# nRF54h20_sysctrl register map
Vendor: Nordic Semiconductor; Series: nRF54h; File version: 1
Registers are 32-bit, read-write, reset 0x0 unless marked. A register's access mark holds for its fields unless they carry their own. Offsets are from the block's base; [hi:lo] are bit positions; lines under a group give offsets from that group; {n}, {i} and the like mark numbered series; 'fields as' and 'values as' point back to an identical list.

## GLOBAL_EGU130 — Event generator unit
Base 0x5F92D000
{0x0+4i} TASKS_TRIGGER[{i}] (i=0..15) wo — Description collection: Trigger n for triggering the corresponding TRIGGERED[n] event
  [0] TASKS_TRIGGER — Trigger n for triggering the corresponding TRIGGERED[n] event
    1=Trigger task
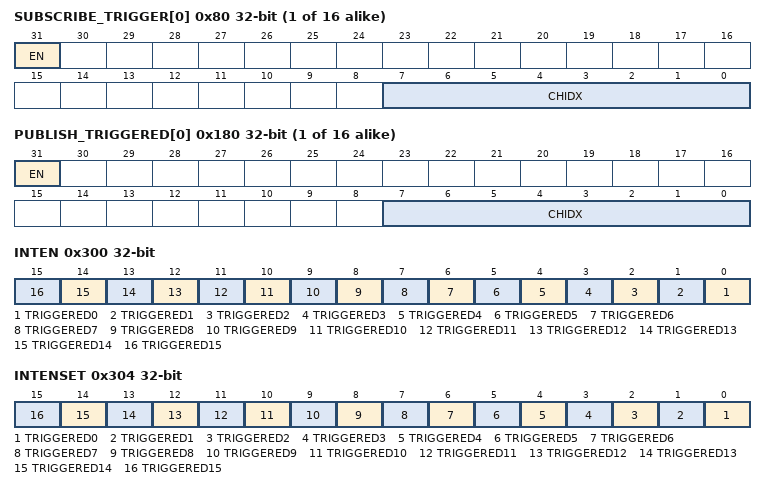
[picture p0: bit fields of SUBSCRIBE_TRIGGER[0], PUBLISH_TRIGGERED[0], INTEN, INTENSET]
{0x80+4i} SUBSCRIBE_TRIGGER[{i}] (i=0..15) — Description collection: Subscribe configuration for task TRIGGER[n]
  [31] EN
    0=Disabled (Disable subscription); 1=Enabled (Enable subscription)
  [7:0] CHIDX — DPPI channel that task TRIGGER[n] will subscribe to
{0x100+4i} EVENTS_TRIGGERED[{i}] (i=0..15) — Description collection: Event number n generated by triggering the corresponding TRIGGER[n] task
  [0] EVENTS_TRIGGERED — Event number n generated by triggering the corresponding TRIGGER[n] task
    0=NotGenerated (Event not generated); 1=Generated (Event generated)
{0x180+4i} PUBLISH_TRIGGERED[{i}] (i=0..15) — Description collection: Publish configuration for event TRIGGERED[n]
  [31] EN
    0=Disabled (Disable publishing); 1=Enabled (Enable publishing)
  [7:0] CHIDX — DPPI channel that event TRIGGERED[n] will publish to
0x300 INTEN — Enable or disable interrupt
  [all] fields
    0=Disabled; 1=Enabled
  [n] TRIGGERED{n} (n=0..15) — Enable or disable interrupt for event TRIGGERED[{n}]
0x304 INTENSET — Enable interrupt
  [all] fields
    on read: 0=Disabled (Read: Disabled); 1=Enabled (Read: Enabled) | on write: 1=Set (Enable)
  [n] TRIGGERED{n} (n=0..15) — Write '1' to enable interrupt for event TRIGGERED[{n}]
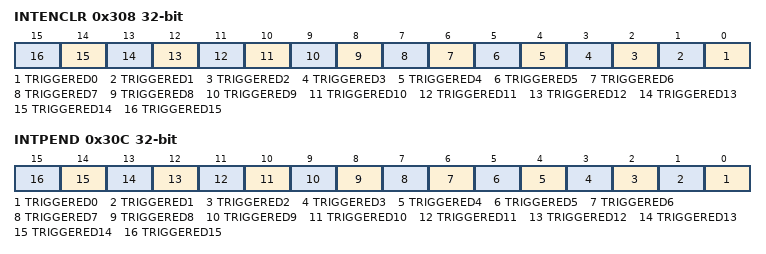
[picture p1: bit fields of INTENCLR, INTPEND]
0x308 INTENCLR — Disable interrupt
  [all] fields
    on read: 0=Disabled (Read: Disabled); 1=Enabled (Read: Enabled) | on write: 1=Clear (Disable)
  [n] TRIGGERED{n} (n=0..15) — Write '1' to disable interrupt for event TRIGGERED[{n}]
0x30C INTPEND ro — Pending interrupts
  [all] fields
    on read: 0=NotPending (Read: Not pending); 1=Pending (Read: Pending)
  [n] TRIGGERED{n} (n=0..15) — Read pending status of interrupt for event TRIGGERED[{n}]

## VDETPOF5V0 — VDETPOF5V0 peripheral
Base 0x5F979000
0x00 TASKS_PWRUP wo — Power up voltage detector
  [0] TASKS_PWRUP
    1=Trigger task
0x04 TASKS_PWRDOWN wo — Power down voltage detector
  [0] TASKS_PWRDOWN
    1=Trigger task
0x100 EVENTS_READY — Power up done
  [0] EVENTS_READY
    0=NotGenerated (Event not generated); 1=Generated (Event generated)
0x108 EVENTS_POFWARN — Power failure warning
  [0] EVENTS_POFWARN
    values as EVENTS_READY.EVENTS_READY
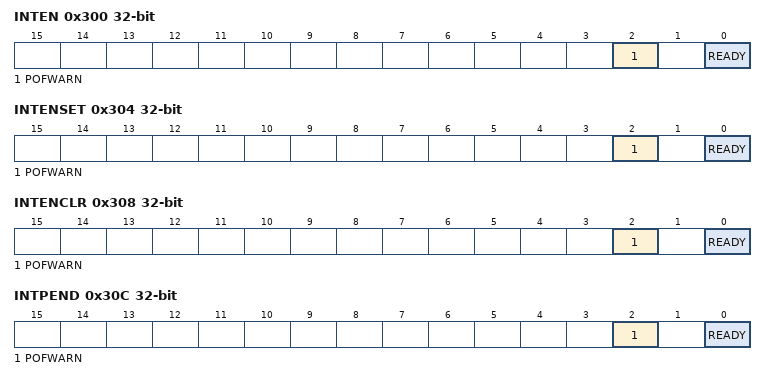
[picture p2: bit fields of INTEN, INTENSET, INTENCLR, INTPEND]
0x300 INTEN — Enable or disable interrupt
  [2] POFWARN — Enable or disable interrupt for event POFWARN
    0=Disabled; 1=Enabled
  [0] READY — Enable or disable interrupt for event READY
    0=Disabled; 1=Enabled
0x304 INTENSET — Enable interrupt
  [2] POFWARN — Write '1' to enable interrupt for event POFWARN
    on read: 0=Disabled (Read: Disabled); 1=Enabled (Read: Enabled) | on write: 1=Set (Enable)
  [0] READY — Write '1' to enable interrupt for event READY
    values as POFWARN
0x308 INTENCLR — Disable interrupt
  [2] POFWARN — Write '1' to disable interrupt for event POFWARN
    on read: 0=Disabled (Read: Disabled); 1=Enabled (Read: Enabled) | on write: 1=Clear (Disable)
  [0] READY — Write '1' to disable interrupt for event READY
    values as POFWARN
0x30C INTPEND ro — Pending interrupts
  [2] POFWARN — Read pending status of interrupt for event POFWARN
    on read: 0=NotPending (Read: Not pending); 1=Pending (Read: Pending)
  [0] READY — Read pending status of interrupt for event READY
    values as POFWARN
0x410 CONFIG group — Unspecified
  0x00 CFG — Voltage detector configuration
    [1:0] POFWARNHYST — Power fail comparator hysteresis voltage value
      0=Val0V050 (Hysteresis voltage is 50mV); 1=Val0V100 (Hysteresis voltage is 100mV); 2=Val0V000 (Hysteresis voltage is 0mV); 3=Val0V025 (Hysteresis voltage is 25mV)
  0x04 POFWARNLVL — Power fail comparator threshold voltage level
    [4:0] VAL — Threshold voltage value.
0x440 TRIM group — Unspecified
  0x00 POFWARN — Power fail comparator trimming
    [2:0] VAL — Threshold voltage trimming value
0x480 MIRROR reset 0x1 — Enable LOCK for mirrored registers
  [0] LOCK — Lock for mirrored registers
    0=Disabled (Lock disabled); 1=Enabled (Lock enabled)

## GLOBAL_TEMP — Temperature Sensor
Base 0x5F984000
0x00 TASKS_START wo — Start temperature measurement
  [0] TASKS_START
    1=Trigger task
0x04 TASKS_STOP wo — Stop temperature measurement
  [0] TASKS_STOP
    1=Trigger task
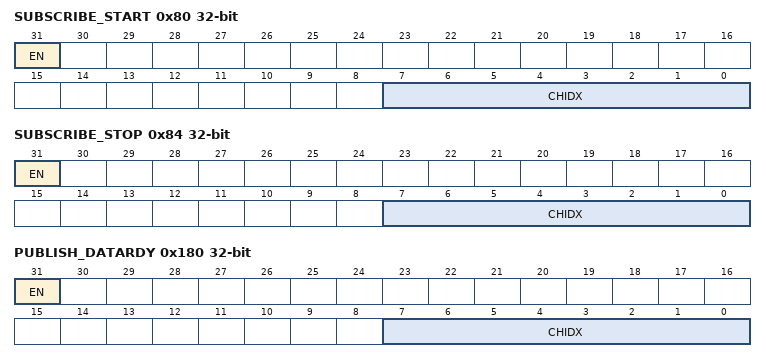
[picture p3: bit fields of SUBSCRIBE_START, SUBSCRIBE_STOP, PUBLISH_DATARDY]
0x80 SUBSCRIBE_START — Subscribe configuration for task START
  [31] EN
    0=Disabled (Disable subscription); 1=Enabled (Enable subscription)
  [7:0] CHIDX — DPPI channel that task START will subscribe to
0x84 SUBSCRIBE_STOP — Subscribe configuration for task STOP
  [31] EN
    values as SUBSCRIBE_START.EN
  [7:0] CHIDX — DPPI channel that task STOP will subscribe to
0x100 EVENTS_DATARDY — Temperature measurement complete, data ready
  [0] EVENTS_DATARDY
    0=NotGenerated (Event not generated); 1=Generated (Event generated)
0x180 PUBLISH_DATARDY — Publish configuration for event DATARDY
  [31] EN
    0=Disabled (Disable publishing); 1=Enabled (Enable publishing)
  [7:0] CHIDX — DPPI channel that event DATARDY will publish to
0x304 INTENSET — Enable interrupt
  [0] DATARDY — Write '1' to enable interrupt for event DATARDY
    on read: 0=Disabled (Read: Disabled); 1=Enabled (Read: Enabled) | on write: 1=Set (Enable)
0x308 INTENCLR — Disable interrupt
  [0] DATARDY — Write '1' to disable interrupt for event DATARDY
    on read: 0=Disabled (Read: Disabled); 1=Enabled (Read: Enabled) | on write: 1=Clear (Disable)
0x508 TEMP ro — Temperature in degC (0.25deg steps)
0x520 A0 reset 0x276 — Slope of 1st piece wise linear function
  [11:0] A0
0x524 A1 reset 0x324 — Slope of 2nd piece wise linear function
  [11:0] A1
0x528 A2 reset 0x3AB — Slope of 3rd piece wise linear function
  [11:0] A2
0x52C A3 reset 0x453 — Slope of 4th piece wise linear function
  [11:0] A3
0x530 A4 reset 0x49B — Slope of 5th piece wise linear function
  [11:0] A4
0x534 A5 reset 0x550 — Slope of 6th piece wise linear function
  [11:0] A5
0x538 A6 reset 0x67E — Slope of 7th piece wise linear function
  [11:0] A6
0x540 B0 reset 0xFA6 — y-intercept of 1st piece wise linear function
  [11:0] B0
0x544 B1 reset 0xF35 — y-intercept of 2nd piece wise linear function
  [11:0] B1
0x548 B2 reset 0xFAA — y-intercept of 3rd piece wise linear function
  [11:0] B2
0x54C B3 reset 0x7E — y-intercept of 4th piece wise linear function
  [11:0] B3
0x550 B4 reset 0xEA — y-intercept of 5th piece wise linear function
  [11:0] B4
0x554 B5 reset 0x1ED — y-intercept of 6th piece wise linear function
  [11:0] B5
0x558 B6 reset 0x378 — y-intercept of 7th piece wise linear function
  [11:0] B6
0x560 T0 reset 0xED — End point of 1st piece wise linear function
  [7:0] T0
0x564 T1 reset 0x13 — End point of 2nd piece wise linear function
  [7:0] T1
0x568 T2 reset 0x29 — End point of 3rd piece wise linear function
  [7:0] T2
0x56C T3 reset 0x3C — End point of 4th piece wise linear function
  [7:0] T3
0x570 T4 reset 0x44 — End point of 5th piece wise linear function
  [7:0] T4
0x574 T5 reset 0x53 — End point of 6th piece wise linear function
  [7:0] T5
